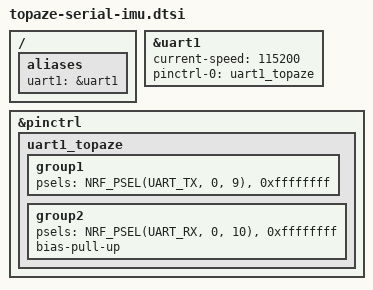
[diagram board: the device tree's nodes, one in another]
/* ============================================================
 * This file is the overlay DTS for topaze that define the UARTS
 *
 * We describe here the peripherals configuration, and so on...
 *
 * l.heywang
 * 01/03/2025
 *
 * ============================================================
 */

// ============================================================
// UARTS and PINCTRL
// ============================================================
// Enable UART drivers with defined settings
&uart1 {
    status = "okay";
    current-speed = <115200>;
    pinctrl-0 = <&uart1_topaze>;
    pinctrl-names = "default";
};

// UART for IMU. No flow control.
// On the DK, exposed pins to an header.
&pinctrl {
    uart1_topaze: uart1_topaze {
        group1 {
            psels = <NRF_PSEL(UART_TX, 0, 9)>,
                    <0xffffffff>; // RTS: Value for unused pin.
                };
        group2 {
            psels = <NRF_PSEL(UART_RX, 0, 10)>,
                    <0xffffffff>; // CTS: Value for unused pin.
                    bias-pull-up;
        };
    };
};

// Configure the console output as UART0 and
// set aliases for this module
/ {
    aliases {
        uart1 = &uart1;
    };
};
